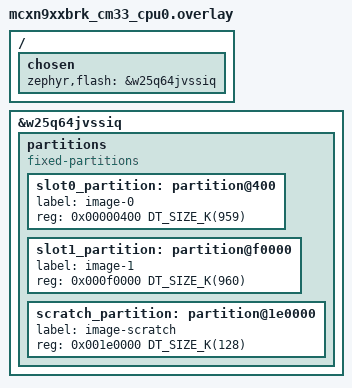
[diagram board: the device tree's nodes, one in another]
/*
 * Copyright 2023 NXP
 *
 * SPDX-License-Identifier: Apache-2.0
 */

/delete-node/ &slot0_partition;
/delete-node/ &slot1_partition;
/delete-node/ &scratch_partition;

/ {
	chosen {
		zephyr,flash = &w25q64jvssiq;
	};
};

&w25q64jvssiq {
	partitions {
		compatible = "fixed-partitions";
		#address-cells = <1>;
		#size-cells = <1>;

		slot0_partition: partition@400 {
			label = "image-0";
			reg = <0x00000400 DT_SIZE_K(959)>;
		};
		slot1_partition: partition@f0000 {
			label = "image-1";
			reg = <0x000f0000 DT_SIZE_K(960)>;
		};
		scratch_partition: partition@1e0000 {
			label = "image-scratch";
			reg = <0x001e0000 DT_SIZE_K(128)>;
		};
	};
};
